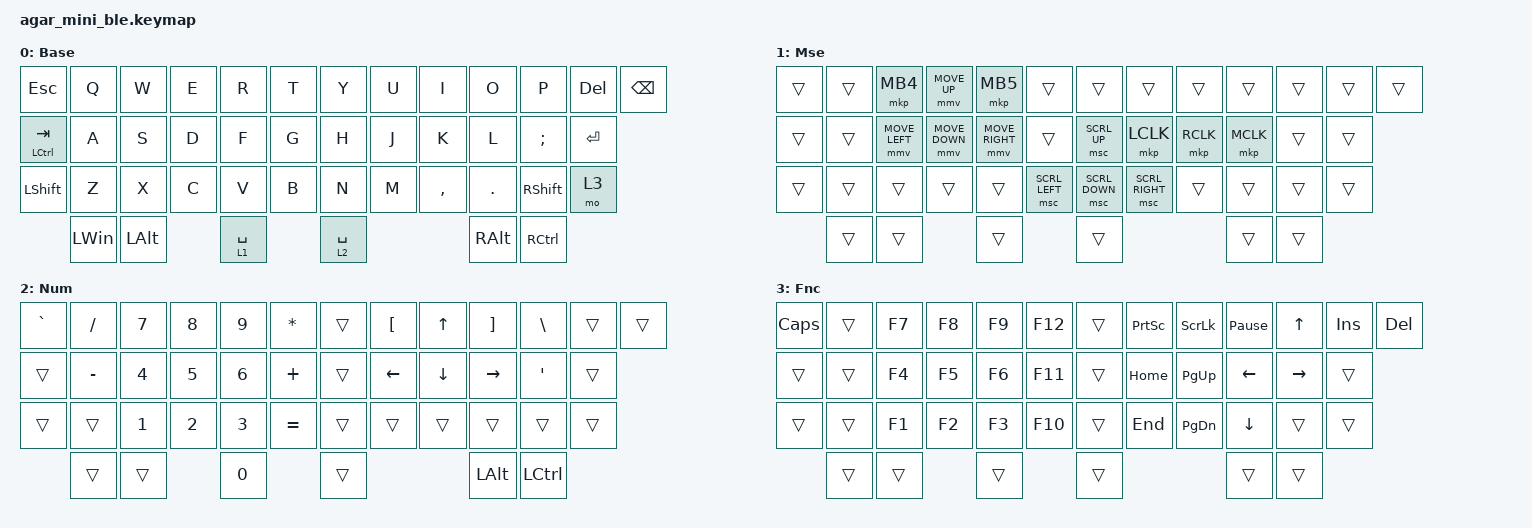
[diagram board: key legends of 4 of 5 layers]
/*
 * Copyright (c) 2021 The ZMK Contributors
 *
 * SPDX-License-Identifier: MIT
 */

#include "./boards/shields/klink_kbd/common.keymap"
#include <behaviors.dtsi>
#include <dt-bindings/zmk/bt.h>
#include <dt-bindings/zmk/keys.h>
#include <dt-bindings/zmk/pointing.h>

#define ZMK_POINTING_DEFAULT_MOVE_VAL 800  // default: 600
#define ZMK_POINTING_DEFAULT_SCRL_VAL 30    // default: 10

/ {
    keymap {
        compatible = "zmk,keymap";

        Base {
            bindings = <
&kp ESC        &kp Q     &kp W     &kp E  &kp R        &kp T  &kp Y        &kp U  &kp I      &kp O     &kp P       &kp DEL  &kp BSPC
&mt LCTRL TAB  &kp A     &kp S     &kp D  &kp F        &kp G  &kp H        &kp J  &kp K      &kp L     &kp SEMI    &kp RET
&kp LSHFT      &kp Z     &kp X     &kp C  &kp V        &kp B  &kp N        &kp M  &kp COMMA  &kp DOT   &kp RSHIFT  &mo 3
               &kp LWIN  &kp LALT         &lt 1 SPACE         &lt 2 SPACE                    &kp RALT  &kp RCTRL
            >;
        };

        Mse {
            bindings = <
&trans  &trans  &mkp MB4        &mmv MOVE_UP    &mkp MB5         &trans          &trans          &trans           &trans     &trans     &trans  &trans  &trans
&trans  &trans  &mmv MOVE_LEFT  &mmv MOVE_DOWN  &mmv MOVE_RIGHT  &trans          &msc SCRL_UP    &mkp LCLK        &mkp RCLK  &mkp MCLK  &trans  &trans
&trans  &trans  &trans          &trans          &trans           &msc SCRL_LEFT  &msc SCRL_DOWN  &msc SCRL_RIGHT  &trans     &trans     &trans  &trans
        &trans  &trans                          &trans                           &trans                                      &trans     &trans
            >;
        };

        Num {
            bindings = <
&kp GRAVE  &kp SLASH  &kp N7  &kp N8  &kp N9  &kp ASTRK  &trans  &kp LBKT  &kp UP    &kp RBKT   &kp BSLH   &trans  &trans
&trans     &kp MINUS  &kp N4  &kp N5  &kp N6  &kp PLUS   &trans  &kp LEFT  &kp DOWN  &kp RIGHT  &kp SQT    &trans
&trans     &trans     &kp N1  &kp N2  &kp N3  &kp EQUAL  &trans  &trans    &trans    &trans     &trans     &trans
           &trans     &trans          &kp N0             &trans                      &kp LALT   &kp LCTRL
            >;
        };

        Fnc {
            bindings = <
&kp CAPS  &trans  &kp F7  &kp F8  &kp F9  &kp F12  &trans  &kp PRINTSCREEN  &kp SCROLLLOCK  &kp PAUSE_BREAK  &kp UP     &kp INS  &kp DEL
&trans    &trans  &kp F4  &kp F5  &kp F6  &kp F11  &trans  &kp HOME         &kp PG_UP       &kp LEFT         &kp RIGHT  &trans
&trans    &trans  &kp F1  &kp F2  &kp F3  &kp F10  &trans  &kp END          &kp PG_DN       &kp DOWN         &trans     &trans
          &trans  &trans          &trans           &trans                                   &trans           &trans
            >;
        };

        Sys {
            bindings = <
&bootloader  &bt BT_SEL 0  &bt BT_SEL 1  &bt BT_SEL 2  &bt BT_SEL 3  &bt BT_SEL 4  &bt BT_CLR  &bt BT_CLR_ALL  &trans  &trans  &trans  &trans  &sys_reset
&trans       &trans        &trans        &trans        &trans        &trans        &trans      &trans          &trans  &trans  &trans  &trans
&trans       &trans        &trans        &trans        &trans        &trans        &trans      &trans          &trans  &trans  &trans  &trans
             &trans        &trans                      &trans                      &trans                              &trans  &trans          &trans
            >;
        };
    };

    conditional_layers {
        compatible = "zmk,conditional-layers";

        Sys_layer {
            if-layers = <1 2>;
            then-layer = <4>;
        };
    };
};
